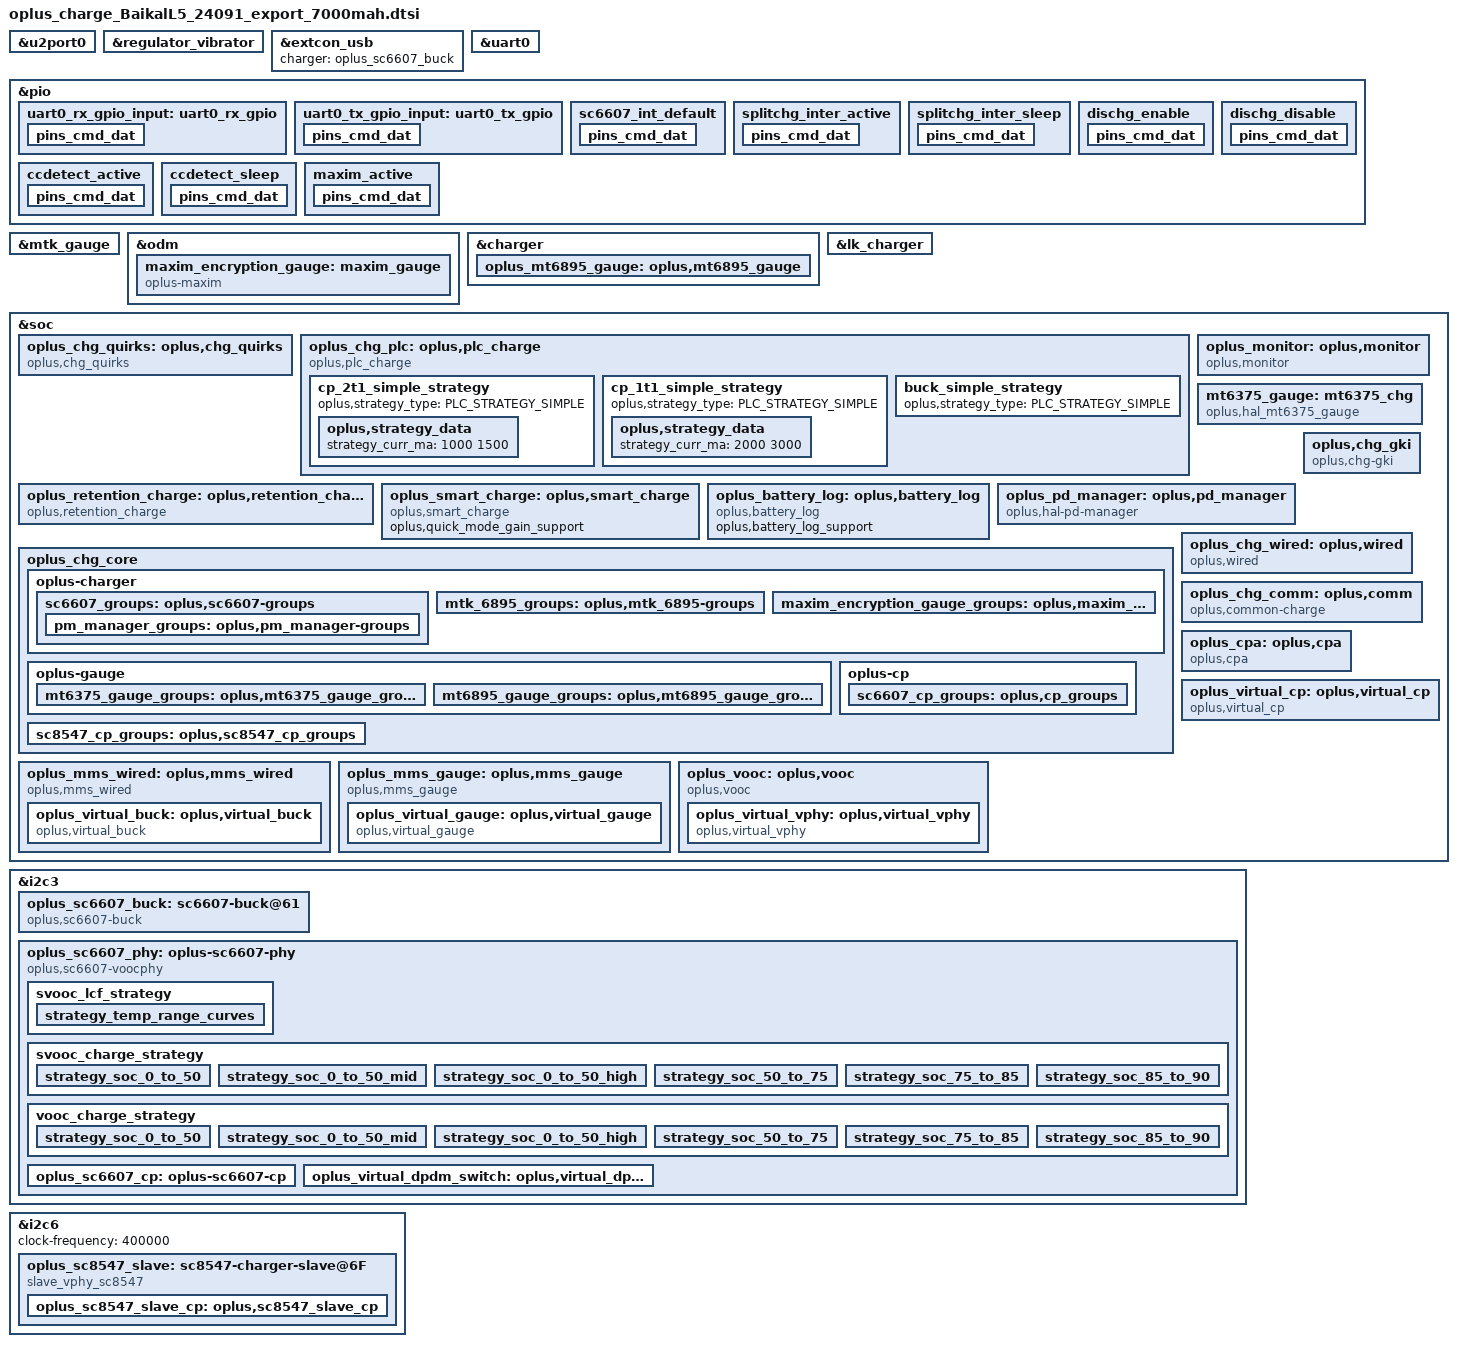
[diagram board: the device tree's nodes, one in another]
// SPDX-License-Identifier: GPL-2.0-only
/*
* Copyright (C) 2021-2020 Oplus. All rights reserved.
*/

/*
 * CPU:MT6835
 * Project:Baikal-L5
 * Module:CHG dtsi 80W support svooc,PPS
 *
 * UART
 * UTXD0 -->GPIO50
 * URXD0 -->GPIO51
 *
 * I2C
 * MASTER_CHG/CCLOGIC --> I2C5
 * Slave_CP --> I2C6
 *
 * IRQ
 * EINT5(PD IRQ)                -->GPIO5
 * EINT6(CHG IRQ)               -->GPIO6
 * EINT18(CP2 IRQ)               -->GPIO18
 *
 * GPIO
 * MAIN/CCLOGIN_SCL               --> GPIO137(SCL5)
 * MAIN/CCLOGIN_SDA               --> GPIO138(SDA5)
 * VBUS_SHORT(防烧口)             --> GPIO34
 * SEC_IC (加密电池GPIO for 80W)      --> GPIO3
 *
 * AP_AUXADC:
 * 0				--> FLASH_LED_NTC (flash light temperature)
 * 1				--> NA
 * 2				--> CHG_NTC(sc6607 charger temperature)
 * 3				--> USB_TEM_ADC_PMU1(usb btb temperature)
 * 4				--> USB_TEM_ADC_PMU2(usb btb temperature)
 * 5				--> BAT_ID(battery id detect)
 * 6				--> TSBAT(Main board battery btb temperature)
 * 7				-->
 * 8				-->
 */

#include <dt-bindings/iio/mt635x-auxadc.h>
#include <dt-bindings/pinctrl/mt6373-pinfunc.h>
#include <dt-bindings/pinctrl/mt65xx.h>
#include "oplus_chg.h"

&u2port0 {
	mediatek,eye-vrt = <7>;
	mediatek,eye-term= <5>;
	mediatek,rev6 = <2>;
	mediatek,eye-vrt-host = <7>;
	mediatek,eye-term-host = <4>;
	mediatek,rev6-host = <2>;
	mediatek,discth = <0xc>;
	mediatek,rx-sqth = <3>;
};

&regulator_vibrator{
	min-volt = <3000000>;
	max-volt = <3000000>;
};

&extcon_usb {
	charger = <&oplus_sc6607_buck>;
	status = "okay";
};

&uart0 {
	pinctrl-names = "uart0_rx_gpio", "uart0_tx_gpio";
	pinctrl-0 = <&uart0_rx_gpio_input>;
	pinctrl-1 = <&uart0_tx_gpio_input>;
	status = "okay";

	txpin = <50>;
	rxpin = <51>;
};

&pio {
	uart0_rx_gpio_input: uart0_rx_gpio {
		pins_cmd_dat {
			pinmux = <PINMUX_GPIO51__FUNC_GPIO51>;
			input-enable;
			slew-rate = <0>;
			bias-disable;
		};
	};

	uart0_tx_gpio_input: uart0_tx_gpio {
		pins_cmd_dat {
			pinmux = <PINMUX_GPIO50__FUNC_GPIO50>;
			input-enable;
			slew-rate = <0>;
			bias-disable;
		};
	};
	sc6607_int_default: sc6607_int_default {
		pins_cmd_dat {
			pinmux = <PINMUX_GPIO6__FUNC_GPIO6>;
			input-enable;
			bias-disable;
			slew-rate = <0>;
		};
	};
	/*split_chg*/
	splitchg_inter_active: splitchg_inter_active {
		pins_cmd_dat {
			pinmux = <PINMUX_GPIO6__FUNC_GPIO6>;
			input-enable;
			bias-pull-up;
			slew-rate = <0>;
		};
	};
	splitchg_inter_sleep: splitchg_inter_sleep {
		pins_cmd_dat {
			pinmux = <PINMUX_GPIO6__FUNC_GPIO6>;
			input-enable;
			bias-pull-down;
			slew-rate = <0>;
		};
	};
	/*VBUS_SHORT*/
	dischg_enable: dischg_enable {
		pins_cmd_dat {
			pinmux = <PINMUX_GPIO34__FUNC_GPIO34>;
			output-high;
		};
	};
	dischg_disable: dischg_disable {
		pins_cmd_dat {
			pinmux = <PINMUX_GPIO34__FUNC_GPIO34>;
			output-low;
		};
	};
	ccdetect_active: ccdetect_active {
		pins_cmd_dat {
			pinmux = <PINMUX_GPIO10__FUNC_GPIO10>;
			input-enable;
			slew-rate = <0>;
			bias-disable;
		};
	};
	ccdetect_sleep: ccdetect_sleep {
		pins_cmd_dat {
			pinmux = <PINMUX_GPIO10__FUNC_GPIO10>;
			input-enable;
			slew-rate = <0>;
			bias-disable;
		};
	};
	maxim_active: maxim_active {
		pins_cmd_dat {
			pinmux = <PINMUX_GPIO3__FUNC_GPIO3>;
			drive-strength = <6>;
			bias-pull-up;
		};
	};
};


&mtk_gauge {
	status = "okay";
	charger = <&oplus_sc6607_buck>;
	//SHUTDOWN_1_TIME = <(10)>;
	FUELGAGUE_APPLY = <(1)>;
	EXTERNAL_AUTHENTICATE =<(1)>;
	IS_SUBBOARD_TEMP_SUPPORT = <(0)>;
	RBAT_PULL_DOWN_R = <(24000)>;
	RBAT_PULL_UP_R = <(12000)>;
	RBAT_PULL_UP_VOLT = <(2800)>;
	USE_MORE_PRECISE_NTC_TABLE = <(1)>;
	//NTC_SERIES_R = <(5100)>;
	FG_METER_RESISTANCE = <(45)>; /* The resistance of PCB */
	CAR_TUNE_VALUE = <(101)>; /* Tune value for current measurement */
	BATT_ID_NEW_4450_CHECK = <(1)>;
	IS_SUBBOARD_TEMP_SUPPORT = <(0)>;
	R_FG_VALUE = <(2)>; /* R_sense resistance */
	oplus,ftm_force_batid = <(1)>; /*need check*/
	AGING_FACTOR_DIFF = <(1)>;
	ACTIVE_TABLE = <(5)>;
	TEMPERATURE_T4 = <(-10)>;
	KEEP_100_PERCENT = <2>;
	KEEP_100_PERCENT_MINSOC = <9500>;
	PSEUDO100_EN = <1>;
	PSEUDO100_EN_DIS = <0>;

	io-channels = <&pmic_adc AUXADC_BAT_TEMP>,
				<&pmic_adc AUXADC_BATADC>,
				<&pmic_adc AUXADC_VBIF>,
				<&pmic_adc AUXADC_IMP>,
				<&pmic_adc AUXADC_IMIX_R>,
				<&auxadc 5>;
	io-channel-names = "pmic_battery_temp",
			   "pmic_battery_voltage",
			   "pmic_bif_voltage",
			   "pmic_ptim_voltage",
			   "pmic_ptim_r",
			   "auxadc5-batt_id_v";


    //IS_SUBBOARD_TEMP_SUPPORT = <(1)>;
	Enable_Is_Force_Full = <(1)>;
	DIM2_TABLE_DISTINGUISH = <(1)>;
	#include "mediatek/bat_setting/mt6835_battery_table_Baikal_L5_7000mah.dtsi"
	#include "mediatek/bat_setting/mt6835_battery_prop_dim2_ext_Baikal_L5.dtsi"
};

&odm {
	maxim_encryption_gauge: maxim_gauge {
		status = "okay";
		compatible = "oplus-maxim";
		pinctrl-names = "maxim_active";
		pinctrl-0 = <&maxim_active>;
		support_encryption_in_lk;
		data-gpio = <&pio 3 0x00>;
		gpio-addr-set-out = <0x10005004>;
		gpio-addr-set-in = <0x10005008>;
		gpio-addr-level_high = <0x10005104>;
		gpio-addr-level_low = <0x10005108>;
		gpio-addr-data-in = <0x10005200>;
		gpio-addr-offset = <0x16>;

		oplus,batt_info = /bits/ 8 <0x36 0x31 0x31 0x33 0x30 0x33 0x30 0x30 0x30 0x32 0x35 0x33
					    0x36 0x31 0x31 0x33 0x30 0x33 0x30 0x30 0x30 0x32 0x35 0x34
					    0x36 0x31 0x31 0x33 0x30 0x33 0x30 0x30 0x30 0x32 0x35 0x35
					    0x36 0x31 0x31 0x33 0x30 0x33 0x30 0x30 0x30 0x32 0x35 0x37>;
		oplus,ic_type = <OPLUS_CHG_IC_GAUGE>;
		oplus,ic_index = <2>;
	};
};

&charger {
	io-channels =<&auxadc 6>,<&auxadc 2>;
	io-channel-names = "auxadc1-ntc_sub_bat_tem","auxadc5-chargeric_temp";
	oplus,support_ntc_01c_precision;
	oplus,support_subboard_ntc;
	oplus,support_subboard_parameter = <1 1 4397119 200000 1800 (-400) 1250 2457>;
	oplus,support_subboard_table = <
	(-40) 4397119 (-40) 4092874 (-40) 3811717 (-40) 3551749 (-40) 3311236 (-40) 3088599
	(-40) 2882396 (-40) 2691310 (-40) 2514137 (-40) 2349778 (-40) 2197225 (-40) 2055558
	(-40) 1923932 (-40) 1801573 (-40) 1687773 (-40) 1581881 (-40) 1483100 (-40) 1391113
	(-40) 1305413 (-40) 1225531 (-40) 1151037 (-40) 1081535 (-40) 1016661 (-40)  956080
	(-40)  899481 (-15) 846579  (-14) 797111  (-13) 750834  (-12)  707524 (-11)  666972
	(-10)  628988 (-9)  593342  (-8)  559931  (-7)  528602  (-6)  499212  (-5)   471632
	(-4)   445772 (-3)  421480  (-2)   398652 (-1) 377193    0    357012   1     338006
	2    320122 3    303287 4    287434 5    272500 6    258426 7    245160
	8    232649 9    220847 10   209710 11   199196 12   189268 13   179890
	14   171028 15   162651 16   154726 17   147232 18   140142 19   133432
	20   127080 21   121066 22   115368 23   109970 24   104852 25   100000
	26   95398  27   91032  28   86889  29   82956  30   79222  31   75675
	32   72306  33   69104  34   66061  35   63167  36   60415  37   57797
	38   55306  39   52934  40   50677  41   48528  42   46482  43   44533
	44   42675  45   40904  46   39213  47   37601  48   36063  49   34595
	50   33195  51   31859  52   30584  53   29366  54   28203  55   27091
	56   26028  57   25013  58   24042  59   23113  60   22224  61   21374
	62   20561  63   19782  64   19036  65   18323  66   17640  67   16986
	68   16360  69   15760  70   15184  71   14631  72   14101  73   13592
	74   13104  75   12635  76   12187  77   11757  78   11344  79   10947
	80   10566  81   10200  82   9848   83   9510   84   9185   85   8873
	86   8572   87   8283   88   8006   89   7738   90   7481   91   7234
	92   6997   93   6769   94   6548   95   6337   96   6132   97   5934
	98   5744   99   5561   100  5384   101  5214   102  5051   103  4893
	104  4741   105  4594   106  4453   107  4316   108  4184   109  4057
	110  3934   111  3816   112  3701   113  3591   114  3484   115  3380
	116  3281   117  3185   118  3093   119  3003   120  2916   121  2832
	122  2751   123  2672   124  2596   125  2522   125  2522   125  2522
	125  2522   125  2522   125   2522  125  2522   125  2522   125  2522
	125  2522   125  2522   125   2522  125  2522   125  2522   125  2522 >;
	max_charger_voltage = <15000000>;
	gauge = <&mtk_gauge>;
	charger = <&oplus_sc6607_buck>;

	oplus,ic_type = <OPLUS_CHG_IC_BUCK>;
	oplus,ic_index = <1>;

	oplus_mt6895_gauge: oplus,mt6895_gauge {
		oplus,ic_type = <OPLUS_CHG_IC_GAUGE>;
		oplus,ic_index = <1>;
	};
};

&lk_charger {
	en_vol_ctrl_vibrate = <3200>;
	support_tuv_authentication;
	support_maxim_battery_authentication;
	data-gpio = <3>;
	oplus,batt_info = /bits/ 8 <0x36 0x31 0x31 0x33 0x30 0x33 0x30 0x30 0x30 0x32 0x35 0x33
				    0x36 0x31 0x31 0x33 0x30 0x33 0x30 0x30 0x30 0x32 0x35 0x34
				    0x36 0x31 0x31 0x33 0x30 0x33 0x30 0x30 0x30 0x32 0x35 0x35
				    0x36 0x31 0x31 0x33 0x30 0x33 0x30 0x30 0x30 0x32 0x35 0x37>;
	charger_no_wiress;
	sdp_screenon_voltage = <3250>;
	sub_board_temp_support;
	sub_board_pull_up_voltage = <1840>;
	sub_board_max_volt_range = <1450>;
	sub_board_pull_up_r = <200000>;
	sub_board_adc_channel = <6>;
	subboard_use_ap_auxadc;
	support_sdp_screenoff;
	support_sdp_backlight;
	led_brightness = <102>;
	high-temp-scheme;
	over_high_temp_thr = <60>;
	support_quickboot_charge;
	is_support_sc6607;
	support_4p48_single_battery;//待确定
	max_charger_voltage = <15000000>;
	boot_battery_voltage = <3400000>;
	usb_charger_current = <500000>;
	ac_charger_current = <2050000>;
	ac_charger_input_current = <1500000>;
	non_std_ac_charger_current = <750000>;
	charging_host_charger_current = <1500000>;
	ta_ac_charger_current = <1500000>;
	pd_charger_current = <500000>;
};

&soc {
	oplus_chg_quirks: oplus,chg_quirks {
		compatible = "oplus,chg_quirks";
	};

	oplus_chg_plc: oplus,plc_charge {
		compatible = "oplus,plc_charge";
		oplus,plc_soc = <90>;
		oplus,plc_strategy-data = <&buck_simple_strategy>;
		oplus,plc_strategy-names = "default";

		cp_2t1_simple_strategy: cp_2t1_simple_strategy {
			oplus,strategy_type = <PLC_STRATEGY_SIMPLE>;
			oplus,strategy_data {
				strategy_curr_ma = <1000 1500>;
			};
		};

		cp_1t1_simple_strategy: cp_1t1_simple_strategy {
			oplus,strategy_type = <PLC_STRATEGY_SIMPLE>;
			oplus,strategy_data {
				strategy_curr_ma = <2000 3000>;
			};
		};

		buck_simple_strategy: buck_simple_strategy {
			oplus,strategy_type = <PLC_STRATEGY_SIMPLE>;
		};
	};

	oplus_retention_charge: oplus,retention_charge {
		compatible = "oplus,retention_charge";
		oplus,topic-update-interval = <5000>;
		oplus,support_retention_name = "oplus_retention_quirks";
	};

	oplus_smart_charge: oplus,smart_charge {
		compatible = "oplus,smart_charge";
		oplus,quick_mode_gain_support;
	};

	oplus_battery_log: oplus,battery_log {
		compatible = "oplus,battery_log";
		oplus,battery_log_support;
	};

	oplus_monitor: oplus,monitor {
		compatible = "oplus,monitor";
		oplus,topic-update-interval = <60000>;

		track,fast_chg_break_t_thd = <1000>;
		track,general_chg_break_t_thd = <200>;
		track,voocphy_type = <3>;
		track,wired_max_power = <80000>;
		track,wired_fast_chg_scheme = <2>;
	};

	mt6375_gauge: mt6375_chg {
		status = "okay";
		compatible = "oplus,hal_mt6375_gauge";

		oplus,ic_type = <OPLUS_CHG_IC_GAUGE>;
		oplus,ic_index = <0>;
		oplus,batt_num = <1>;
		oplus,mtk_gauge_power_sel_support;
		oplus,mtk_gauge_power_sel_by_power_support;
		oplus,mtk_gauge_cali_track_support;
	};

	oplus_pd_manager: oplus,pd_manager{
		compatible = "oplus,hal-pd-manager";
		oplus,ic_type = <OPLUS_CHG_IC_TYPEC>;
		oplus,ic_index = <0>;
	};

	oplus,chg_gki {
		compatible = "oplus,chg-gki";
	};

	oplus_chg_core {
		oplus,chg_framework_v2;
		oplus,chg_spec_version = <OPLUS_CHG_SPEC_VER_V3P7>;
		oplus,smart_charging_screenoff;

		oplus-charger {
			sc6607_groups: oplus,sc6607-groups {
				functions = <
					OPLUS_IC_FUNC_INIT
					OPLUS_IC_FUNC_EXIT
					OPLUS_IC_FUNC_REG_DUMP
					OPLUS_IC_FUNC_SMT_TEST
					OPLUS_IC_FUNC_BUCK_INPUT_PRESENT
					OPLUS_IC_FUNC_BUCK_INPUT_SUSPEND
					OPLUS_IC_FUNC_BUCK_INPUT_IS_SUSPEND
					OPLUS_IC_FUNC_BUCK_OUTPUT_SUSPEND
					OPLUS_IC_FUNC_BUCK_OUTPUT_IS_SUSPEND
					OPLUS_IC_FUNC_BUCK_SET_ICL
					OPLUS_IC_FUNC_BUCK_GET_ICL
					OPLUS_IC_FUNC_BUCK_SET_FCC
					OPLUS_IC_FUNC_BUCK_SET_FV
					OPLUS_IC_FUNC_BUCK_SET_ITERM
					OPLUS_IC_FUNC_BUCK_SET_RECHG_VOL
					OPLUS_IC_FUNC_BUCK_GET_INPUT_CURR
					OPLUS_IC_FUNC_BUCK_GET_INPUT_VOL
					OPLUS_IC_FUNC_OTG_BOOST_ENABLE
					OPLUS_IC_FUNC_SET_OTG_BOOST_VOL
					OPLUS_IC_FUNC_BUCK_AICL_ENABLE
					OPLUS_IC_FUNC_BUCK_AICL_RERUN
					OPLUS_IC_FUNC_BUCK_AICL_RESET
					OPLUS_IC_FUNC_BUCK_GET_CHARGER_TYPE
					OPLUS_IC_FUNC_BUCK_RERUN_BC12
					OPLUS_IC_FUNC_BUCK_QC_DETECT_ENABLE
					OPLUS_IC_FUNC_BUCK_SET_QC_CONFIG
					OPLUS_IC_FUNC_BUCK_SHIPMODE_ENABLE
					OPLUS_IC_FUNC_BUCK_GET_USB_BTB_TEMP
					OPLUS_IC_FUNC_BUCK_GET_BATT_BTB_TEMP
					OPLUS_IC_FUNC_BUCK_SET_AICL_POINT
					OPLUS_IC_FUNC_BUCK_HARDWARE_INIT
					OPLUS_IC_FUNC_BUCK_KICK_WDT
					OPLUS_IC_FUNC_BUCK_GET_USB_AICL_ENHANCE
					OPLUS_IC_FUNC_BUCK_SET_FLASH_MODE
					OPLUS_IC_FUNC_BUCK_SET_PD_CONFIG
				>;
				virqs = <
					OPLUS_IC_VIRQ_ERR
					OPLUS_IC_VIRQ_PLUGIN
					OPLUS_IC_VIRQ_CHG_TYPE_CHANGE
					OPLUS_IC_VIRQ_BC12_COMPLETED
				>;
				pm_manager_groups: oplus,pm_manager-groups {
					functions = <
						OPLUS_IC_FUNC_INIT
						OPLUS_IC_FUNC_EXIT
						OPLUS_IC_FUNC_REG_DUMP
						OPLUS_IC_FUNC_SMT_TEST
						OPLUS_IC_FUNC_BUCK_GET_CHARGER_TYPE
						OPLUS_IC_FUNC_BUCK_GET_CC_ORIENTATION
						OPLUS_IC_FUNC_BUCK_SET_PD_CONFIG
						OPLUS_IC_FUNC_GET_TYPEC_MODE
						OPLUS_IC_FUNC_SET_TYPEC_MODE
						OPLUS_IC_FUNC_GET_TYPEC_ROLE
						OPLUS_IC_FUNC_GET_CHARGER_VOL_MAX
						OPLUS_IC_FUNC_GET_CHARGER_VOL_MIN
						OPLUS_IC_FUNC_GET_CHARGER_CURR_MAX
						OPLUS_IC_FUNC_BUCK_BC12_COMPLETED
						OPLUS_IC_FUNC_GET_OTG_ENABLE
						OPLUS_IC_FUNC_IS_OPLUS_SVID
						OPLUS_IC_FUNC_GET_DATA_ROLE
						OPLUS_IC_FUNC_FIXED_PDO_SET
						OPLUS_IC_FUNC_PPS_PDO_SET
						OPLUS_IC_FUNC_PPS_GET_PDO_INFO
					>;
					virqs = <
						OPLUS_IC_VIRQ_ERR
						OPLUS_IC_VIRQ_CHG_TYPE_CHANGE
						OPLUS_IC_VIRQ_SVID
						OPLUS_IC_VIRQ_VOLTAGE_CHANGED
						OPLUS_IC_VIRQ_CURRENT_CHANGED
						OPLUS_IC_VIRQ_OTG_ENABLE
						OPLUS_IC_VIRQ_DATA_ROLE_CHANGED
						OPLUS_IC_VIRQ_CC_DETECT
					>;
				};
			};
			mtk_6895_groups: oplus,mtk_6895-groups {
				functions = <
					OPLUS_IC_FUNC_INIT
					OPLUS_IC_FUNC_EXIT
					OPLUS_IC_FUNC_REG_DUMP
					OPLUS_IC_FUNC_SMT_TEST
				>;
				virqs = <
					OPLUS_IC_VIRQ_ERR
				>;
			};

			maxim_encryption_gauge_groups: oplus,maxim_encryption_gauge_groups {
				functions = <
					OPLUS_IC_FUNC_INIT
					OPLUS_IC_FUNC_EXIT
					OPLUS_IC_FUNC_GAUGE_GET_BATT_AUTH
				>;
				virqs = <
					OPLUS_IC_VIRQ_ERR
				>;
			};
		};

		oplus-gauge {
			mt6375_gauge_groups: oplus,mt6375_gauge_groups {
				functions = <
					OPLUS_IC_FUNC_INIT
					OPLUS_IC_FUNC_EXIT
					OPLUS_IC_FUNC_REG_DUMP
					OPLUS_IC_FUNC_SMT_TEST
					OPLUS_IC_FUNC_GAUGE_GET_BATT_VOL
					OPLUS_IC_FUNC_GAUGE_GET_BATT_MAX
					OPLUS_IC_FUNC_GAUGE_GET_BATT_MIN
					OPLUS_IC_FUNC_GAUGE_GET_BATT_CURR
					OPLUS_IC_FUNC_GAUGE_GET_BATT_TEMP
					OPLUS_IC_FUNC_GAUGE_GET_BATT_SOC
					OPLUS_IC_FUNC_GAUGE_GET_BATT_FCC
					OPLUS_IC_FUNC_GAUGE_GET_BATT_CC
					OPLUS_IC_FUNC_GAUGE_GET_BATT_RM
					OPLUS_IC_FUNC_GAUGE_GET_BATT_SOH
					OPLUS_IC_FUNC_GAUGE_GET_BATT_HMAC
					OPLUS_IC_FUNC_GAUGE_SET_BATT_FULL
					OPLUS_IC_FUNC_GAUGE_UPDATE_DOD0
					OPLUS_IC_FUNC_GAUGE_UPDATE_SOC_SMOOTH
					OPLUS_IC_FUNC_GAUGE_GET_CB_STATUS
					OPLUS_IC_FUNC_GAUGE_GET_BATT_NUM
					OPLUS_IC_FUNC_GAUGE_GET_DEVICE_TYPE
					OPLUS_IC_FUNC_GAUGE_GET_DEVICE_TYPE_FOR_VOOC
					OPLUS_IC_FUNC_GAUGE_GET_BATT_FCC
					OPLUS_IC_FUNC_GAUGE_GET_BATT_FC
					OPLUS_IC_FUNC_GAUGE_GET_BATT_QM
					OPLUS_IC_FUNC_GAUGE_GET_BATT_PD
					OPLUS_IC_FUNC_GAUGE_GET_BATT_RCU
					OPLUS_IC_FUNC_GAUGE_GET_BATT_RCF
					OPLUS_IC_FUNC_GAUGE_GET_BATT_FCU
					OPLUS_IC_FUNC_GAUGE_GET_BATT_FCF
					OPLUS_IC_FUNC_GAUGE_GET_BATT_SOU
					OPLUS_IC_FUNC_GAUGE_GET_BATT_DO0
					OPLUS_IC_FUNC_GAUGE_GET_BATT_DOE
					OPLUS_IC_FUNC_GAUGE_GET_BATT_TRM
					OPLUS_IC_FUNC_GAUGE_GET_BATT_PC
					OPLUS_IC_FUNC_GAUGE_GET_BATT_QS
					OPLUS_IC_FUNC_GAUGE_IS_SUSPEND
					OPLUS_IC_FUNC_GAUGE_GET_BCC_PARMS
					OPLUS_IC_FUNC_GAUGE_FASTCHG_UPDATE_BCC_PARMS
					OPLUS_IC_FUNC_GAUGE_GET_PREV_BCC_PARMS
					OPLUS_IC_FUNC_GAUGE_SET_BCC_PARMS
					OPLUS_IC_FUNC_GAUGE_SET_PROTECT_CHECK
					OPLUS_IC_FUNC_GAUGE_GET_AFI_UPDATE_DONE
					OPLUS_IC_FUNC_GAUGE_CHECK_RESET
					OPLUS_IC_FUNC_GAUGE_GET_DEVICE_TYPE_FOR_BCC
					OPLUS_IC_FUNC_GAUGE_GET_DOD0
					OPLUS_IC_FUNC_GAUGE_GET_DOD0_PASSED_Q
					OPLUS_IC_FUNC_GAUGE_GET_QMAX
					OPLUS_IC_FUNC_GAUGE_GET_QMAX_PASSED_Q
					OPLUS_IC_FUNC_GAUGE_SET_BATTERY_CURVE
					OPLUS_IC_FUNC_GAUGE_GET_GAUGE_TYPE
					OPLUS_IC_FUNC_GAUGE_GET_GAUGE_CAR_C
					OPLUS_IC_FUNC_GAUGE_GET_DEC_FG_TYPE
					OPLUS_IC_FUNC_GAUGE_GET_DEC_CV_SOH
					OPLUS_IC_FUNC_GAUGE_SET_VCT
					OPLUS_IC_FUNC_GAUGE_GET_VCT
				>;
				virqs = <
					OPLUS_IC_VIRQ_ERR
					OPLUS_IC_VIRQ_OFFLINE
					OPLUS_IC_VIRQ_RESUME
				>;
			};

			mt6895_gauge_groups: oplus,mt6895_gauge_groups {
				functions = <
					OPLUS_IC_FUNC_INIT
					OPLUS_IC_FUNC_EXIT
					OPLUS_IC_FUNC_GAUGE_GET_SUBBOARD_TEMP
				>;
				virqs = <
					OPLUS_IC_VIRQ_ERR
				>;
			};
		};

		oplus-cp {
			sc6607_cp_groups: oplus,cp_groups {
			functions = <
					OPLUS_IC_FUNC_INIT
					OPLUS_IC_FUNC_EXIT
					OPLUS_IC_FUNC_REG_DUMP
					OPLUS_IC_FUNC_SMT_TEST
					OPLUS_IC_FUNC_CP_ENABLE
					OPLUS_IC_FUNC_CP_HW_INTI
					OPLUS_IC_FUNC_CP_GET_WORK_MODE
					OPLUS_IC_FUNC_CP_CHECK_WORK_MODE_SUPPORT
					OPLUS_IC_FUNC_CP_SET_WORK_MODE
					OPLUS_IC_FUNC_CP_GET_VIN
					OPLUS_IC_FUNC_CP_GET_IIN
					OPLUS_IC_FUNC_CP_SET_IIN
					OPLUS_IC_FUNC_CP_GET_VOUT
					OPLUS_IC_FUNC_CP_GET_IOUT
					OPLUS_IC_FUNC_CP_GET_VAC
					OPLUS_IC_FUNC_CP_SET_IIN
					OPLUS_IC_FUNC_CP_SET_WORK_START
					OPLUS_IC_FUNC_CP_GET_WORK_STATUS
					OPLUS_IC_FUNC_CP_SET_ADC_ENABLE
					OPLUS_IC_FUNC_CP_WATCHDOG_ENABLE
					OPLUS_IC_FUNC_CP_WATCHDOG_RESET
					OPLUS_IC_FUNC_CP_SET_UCP_DISABLE
					OPLUS_IC_FUNC_CP_GET_IIN_MAX
				>;
				virqs = <
					OPLUS_IC_VIRQ_ERR
					OPLUS_IC_VIRQ_ONLINE
					OPLUS_IC_VIRQ_OFFLINE
				>;
			};
		};
		sc8547_cp_groups: oplus,sc8547_cp_groups {
				functions = <
					OPLUS_IC_FUNC_INIT
					OPLUS_IC_FUNC_EXIT
					OPLUS_IC_FUNC_REG_DUMP
					OPLUS_IC_FUNC_SMT_TEST
					OPLUS_IC_FUNC_CP_ENABLE
					OPLUS_IC_FUNC_CP_HW_INTI
					OPLUS_IC_FUNC_CP_SET_WORK_START
					OPLUS_IC_FUNC_CP_CHECK_WORK_MODE_SUPPORT
					OPLUS_IC_FUNC_CP_SET_WORK_MODE
					OPLUS_IC_FUNC_CP_GET_WORK_MODE
					OPLUS_IC_FUNC_CP_GET_VIN
					OPLUS_IC_FUNC_CP_GET_IIN
					OPLUS_IC_FUNC_CP_SET_IIN
					OPLUS_IC_FUNC_CP_GET_VOUT
					OPLUS_IC_FUNC_CP_GET_IOUT
					OPLUS_IC_FUNC_CP_GET_VAC
					OPLUS_IC_FUNC_CP_GET_WORK_STATUS
					OPLUS_IC_FUNC_CP_SET_ADC_ENABLE
					OPLUS_IC_FUNC_CP_WATCHDOG_ENABLE
				>;
				virqs = <
					OPLUS_IC_VIRQ_ERR
					OPLUS_IC_VIRQ_ONLINE
					OPLUS_IC_VIRQ_OFFLINE
				>;
			};
	};
};

&soc {
	oplus_mms_wired: oplus,mms_wired {
		compatible = "oplus,mms_wired";
		oplus,buck_ic = <&oplus_virtual_buck>;
		oplus,voocphy_ic = <&oplus_virtual_vphy>;
		oplus,adc_info_name = "100k_1800mv";
		oplus_spec,usbtemp_batttemp_gap = <12>;
		high-temp-scheme;

		oplus,support_usbtemp_protect_v2;
		oplus_spec,usbtemp_batt_temp_low = <50>;
		oplus_spec,usbtemp_batt_temp_high = <50>;
		oplus_spec,usbtemp_batt_temp_over_hot = <60>;
		oplus_spec,usbtemp_ntc_temp_low = <57>;
		oplus_spec,usbtemp_ntc_temp_high = <69>;
		oplus_spec,usbtemp_temp_gap_low_with_batt_temp = <7>;
		oplus_spec,usbtemp_temp_gap_with_batt_temp_in_over_hot = <15>;
		oplus_spec,usbtemp_temp_gap_high_with_batt_temp = <12>;
		oplus_spec,usbtemp_temp_gap_low_without_batt_temp = <12>;
		oplus_spec,usbtemp_temp_gap_high_without_batt_temp = <24>;
		oplus_spec,usbtemp_rise_fast_temp_low = <3>;
		oplus_spec,usbtemp_rise_fast_temp_high = <3>;
		oplus_spec,usbtemp_rise_fast_temp_count_low = <30>;
		oplus_spec,usbtemp_rise_fast_temp_count_high = <20>;
		oplus_spec,usbtemp_cool_down_ntc_low = <54>;
		oplus_spec,usbtemp_cool_down_ntc_high = <65>;
		oplus_spec,usbtemp_cool_down_gap_low = <12>;
		oplus_spec,usbtemp_cool_down_gap_high = <20>;
		oplus_spec,usbtemp_cool_down_recover_ntc_low = <48>;
		oplus_spec,usbtemp_cool_down_recover_ntc_high = <60>;
		oplus_spec,usbtemp_cool_down_recover_gap_low = <6>;
		oplus_spec,usbtemp_cool_down_recover_gap_high = <15>;
		oplus_virtual_buck: oplus,virtual_buck {
			compatible = "oplus,virtual_buck";
			oplus,buck_ic = <&oplus_sc6607_buck &oplus_pd_manager &charger>;
			oplus,buck_ic_index = <0 1 2>;
			oplus,buck_ic_current_ratio = <100 0 0>;
			oplus,buck_ic_connect = <OPLUS_CHG_IC_CONNECT_PARALLEL>;
			oplus,main_charger = <0>;
			oplus,buck_ic_func_group = <&sc6607_groups &pm_manager_groups &mtk_6895_groups>;
			oplus,ic_type = <OPLUS_CHG_IC_VIRTUAL_BUCK>;
			oplus,ic_index = <0>;
			oplus,dischg-gpio = <&pio 34 0x00>;/*VBUS_SHORT*/
			oplus,ccdetect-gpio = <&pio 10 0x00>;
			oplus,uart_tx-gpio = <&pio 50 0x00>;
			oplus,uart_rx-gpio = <&pio 51 0x00>;
			pinctrl-names = "dischg_enable", "dischg_disable",
						"ccdetect_active", "ccdetect_sleep";
			pinctrl-0 = <&dischg_enable>;
			pinctrl-1 = <&dischg_disable>;
			pinctrl-2 = <&ccdetect_active>;
			pinctrl-3 = <&ccdetect_sleep>;
			io-channels = <&auxadc 4>,<&auxadc 3>;
			io-channel-names = "usb_temp_adc_l","usb_temp_adc_r";
		};
	};
	oplus_mms_gauge: oplus,mms_gauge {
		compatible = "oplus,mms_gauge";
		oplus,voocphy_ic = <&oplus_virtual_vphy>;
		oplus,gauge_ic = <&oplus_virtual_gauge>;
		oplus,topic-update-interval = <10000>;
		oplus,support_subboard_ntc;
		oplus_virtual_gauge: oplus,virtual_gauge {
			compatible = "oplus,virtual_gauge";
			oplus,gauge_ic = <&mt6375_gauge &oplus_mt6895_gauge &maxim_encryption_gauge>;
			oplus,gauge_ic_index = <0 1 2>;
			oplus,gauge_ic_func_group = <&mt6375_gauge_groups &mt6895_gauge_groups &maxim_encryption_gauge_groups>;
			oplus,batt_capacity_mah = <7000>;
			oplus,ic_type = <OPLUS_CHG_IC_VIRTUAL_GAUGE>;
			oplus,ic_index = <0>;
		};
	};
};

&soc {
	oplus_chg_wired: oplus,wired {
		compatible = "oplus,wired";
		oplus,vooc-support;
		oplus_spec,vbatt_pdqc_to_5v_thr = <4500>;
		oplus_spec,vbatt_pdqc_to_9v_thr = <4500>;
		oplus_spec,pd-iclmax-ma = <1500>;
		oplus_spec,qc-iclmax-ma = <1500>;
		oplus_spec,non-standard-ibatmax-ma = <500>;
		oplus_spec,input-power-mw = <
			2500		/* OPLUS_WIRED_CHG_MODE_UNKNOWN */
			2500		/* OPLUS_WIRED_CHG_MODE_SDP */
			7500		/* OPLUS_WIRED_CHG_MODE_CDP */
			10000		/* OPLUS_WIRED_CHG_MODE_DCP */
			18000		/* OPLUS_WIRED_CHG_MODE_VOOC */
			13500		/* OPLUS_WIRED_CHG_MODE_QC */
			13500		/* OPLUS_WIRED_CHG_MODE_PD */
		>;
		oplus_spec,led_on-fccmax-ma = <0 1707 3300 3300 3300 3300 3300 1000 0>;
		oplus_spec,fccmax-ma-lv = <
			0 1200 2200 2200 2200 2200 2200 2200 0	/* OPLUS_WIRED_CHG_MODE_UNKNOWN */
			0 600  600  600  600  600  600  600  0	/* OPLUS_WIRED_CHG_MODE_SDP */
			0 1600 1600 1600 1600 1600 1600 1600 0	/* OPLUS_WIRED_CHG_MODE_CDP */
			0 1707 2200 2200 2200 2200 2200 2200 0	/* OPLUS_WIRED_CHG_MODE_DCP */
			0 1707 3300 3300 3300 3300 3300 3300 0	/* OPLUS_WIRED_CHG_MODE_VOOC */
			0 1707 3300 3300 3300 3300 3300 3300 0	/* OPLUS_WIRED_CHG_MODE_QC */
			0 1707 3300 3300 3300 3300 3300 3300 0	/* OPLUS_WIRED_CHG_MODE_PD */
		>;
		oplus_spec,fccmax-ma-hv = <
			0 1200 2200 2200 2200 2200 2200 2200 0	/* OPLUS_WIRED_CHG_MODE_UNKNOWN */
			0 600  600  600  600  600  600  600  0	/* OPLUS_WIRED_CHG_MODE_SDP */
			0 1600 1600 1600 1600 1600 1600 1600 0	/* OPLUS_WIRED_CHG_MODE_CDP */
			0 1707 2200 2200 2200 2200 2200 2200 0	/* OPLUS_WIRED_CHG_MODE_DCP */
			0 1707 3300 3300 3300 3300 3300 3300 0	/* OPLUS_WIRED_CHG_MODE_VOOC */
			0 1707 3300 3300 3300 3300 3300 3300 0	/* OPLUS_WIRED_CHG_MODE_QC */
			0 1707 3300 3300 3300 3300 3300 3300 0	/* OPLUS_WIRED_CHG_MODE_PD */
		>;

		oplus_spec,cool_down_sale_pdqc_vol_mv = <5000>;
		oplus_spec,cool_down_sale_pdqc_curr_ma = <1200>;
		oplus_spec,cool_down_pdqc_vol_mv = <5000 5000 5000 9000>;
		oplus_spec,cool_down_pdqc_curr_ma = <1200 1500 2000 1500>;
		oplus_spec,cool_down_vooc_curr_ma = <1200 1500 2000 2500 3000 3000>;
		oplus_spec,cool_down_normal_curr_ma = <1200 1500 2000>;

		oplus_spec,vbus_ov_thr_mv = <10000 10000>;
		oplus_spec,vbus_uv_thr_mv = <4300 4300>;

		/* first data is strategy used temp type */
		oplus,vooc_strategy_name = "cgcl";
		oplus,vooc_strategy_data = <OPLUS_STRATEGY_USE_BATT_TEMP
					    0   350 3000 1 0
					    330 370 3000 2 0
					    350 440 2200 2 1>;
	};

	oplus_chg_comm: oplus,comm {
		compatible = "oplus,common-charge";
		oplus_spec,dec_step = <20>;
		oplus_spec,dec-vol-cc-full-thr = <0 400 600 800 1000 1200>;
		oplus_spec,dec-vol-fv-full-mv = <0 20 20 40 40 40>;
		oplus_spec,batt-them-thr = <(-100) 0 50 120 160 350 450 530>;
		oplus_spec,iterm-ma = <352>;
		oplus_spec,removed_bat_decidegc = <390>; /*-39 degree*/
		oplus_spec,fv-mv = <4490 4490 4490 4490 4490 4490 4470 4130 4130>;
		oplus_spec,sw-fv-mv = <4440 4440 4440 4440 4440 4440 4420 4080 4080>;
		oplus_spec,hw-fv-inc-mv = <0 18 18 18 18 18 18 18 0>;
		oplus_spec,sw-over-fv-mv = <4500 4500 4500 4500 4500 4500 4480 4140 4140>;
		oplus_spec,sw-over-fv-dec-mv = <8>;
		oplus_spec,non-standard-sw-fv-mv = <3930>;
		oplus_spec,non-standard-fv-mv = <3980>;
		oplus_spec,non-standard-hw-fv-inc-mv = <18>;
		oplus_spec,non-standard-sw-over-fv-mv = <3990>;
		oplus_spec,non-standard-vbatdet-mv = <3680>;
		oplus_spec,wired-vbatdet-mv = <0 4190 4290 4390 4390 4390 4370 4030 0>;
		oplus_spec,fcc-gear-thr-mv = <4180>;
		oplus_spec,vbatt-ov-thr-mv = <4600>;

		oplus_spec,full_pre_ffc_judge;
		oplus_spec,full-pre-ffc-mv = <4485>;
		oplus_spec,ffc-temp-thr = <120 210 350 440>;
		oplus_spec,wired-ffc-step-max = <2>;
		oplus_spec,wired-ffc-fv-mv = <4630 4630>;

		oplus_spec,wired-ffc-fv-cutoff-mv = <4565 4525 4525
						     4565 4505 4505>;
		oplus_spec,wired-ffc-fcc-ma = <1500 1500 1500
					       1440 1000 1000>;
		oplus_spec,wired-ffc-fcc-cutoff-ma = <1300 1300 1300
						      1340 900 900>;
		oplus_spec,vbat_uv_thr_mv = <3300>;
		oplus_spec,vbat_charging_uv_thr_mv = <3200>;

		/*If use subboard NTC as battery temp, config it as 20, otherwise 0 */
		oplus_spec,tbatt_power_off_cali_temp = <0>;
		oplus_spec,poweroff_high_batt_temp = <720>;
		oplus_spec,poweroff_emergency_batt_temp = <770>;
		oplus,vooc_show_ui_soc_decimal;
		oplus,ui_soc_decimal_speedmin = <20>;
		oplus,gauge_stuck_jump_support;
		oplus,gauge_stuck_threshold = <15>;
		oplus,gauge_stuck_time = <50>;
	};

	oplus_vooc: oplus,vooc {
		compatible = "oplus,vooc";
		oplus,vooc_ic = <&oplus_virtual_vphy>;
		oplus_spec,vooc_soc_range = <50 75 85>;
		oplus_spec,vooc_temp_range = <50 120 180 350 450>;
		oplus,vooc_data_width = <7>;
		oplus,vooc_curr_max = <CP_CURR_LIMIT_7BIT_15_0A>; /* 80W: 11V 7.3A(IBUS *2) */
		oplus,vooc_project = <7>;
		oplus,vooc_curr_table_type = <VOOC_CP_CURR_TABLE>;
		oplus,vooc_power_max_w = <80>;
		oplus,voocphy_support = <3>;  /* AP_DUAL_CP_VOOCPHY */
		oplus,support_fake_vooc_check;
		oplus,subboard_ntc_abnormal_current = <4000>;
		oplus,cp_cooldown_limit_percent_75 = <CP_CURR_LIMIT_7BIT_8_0A>;
		oplus,cp_cooldown_limit_percent_85 = <CP_CURR_LIMIT_7BIT_4_0A>;
		oplus,abnormal_adapter_current = <CP_CURR_LIMIT_7BIT_15_0A CP_CURR_LIMIT_7BIT_15_0A
						CP_CURR_LIMIT_7BIT_12_6A CP_CURR_LIMIT_7BIT_12_6A
						CP_CURR_LIMIT_7BIT_10_0A CP_CURR_LIMIT_7BIT_10_0A
						CP_CURR_LIMIT_7BIT_8_0A CP_CURR_LIMIT_7BIT_8_0A
						CP_CURR_LIMIT_7BIT_6_0A CP_CURR_LIMIT_7BIT_6_0A
						CP_CURR_LIMIT_7BIT_4_0A CP_CURR_LIMIT_7BIT_4_0A>;

		oplus,abnormal_over_80w_adapter_current = <CP_CURR_LIMIT_7BIT_15_0A CP_CURR_LIMIT_7BIT_15_0A
						CP_CURR_LIMIT_7BIT_14_0A CP_CURR_LIMIT_7BIT_14_0A
						CP_CURR_LIMIT_7BIT_12_0A CP_CURR_LIMIT_7BIT_12_0A
						CP_CURR_LIMIT_7BIT_10_0A CP_CURR_LIMIT_7BIT_10_0A
						CP_CURR_LIMIT_7BIT_8_0A CP_CURR_LIMIT_7BIT_8_0A
						CP_CURR_LIMIT_7BIT_6_0A CP_CURR_LIMIT_7BIT_6_0A
						CP_CURR_LIMIT_7BIT_4_0A CP_CURR_LIMIT_7BIT_4_0A>;
		/* first data is strategy used temp type */
		oplus,general_strategy_name = "cgcl";
		oplus,general_strategy_data = < OPLUS_STRATEGY_USE_SHELL_TEMP
						0   370 CP_CURR_LIMIT_7BIT_15_0A 1 0
						375 383 CP_CURR_LIMIT_7BIT_9_0A 2 0
						390 420 CP_CURR_LIMIT_7BIT_7_0A 3 1
						420 440 CP_CURR_LIMIT_7BIT_3_0A 3 2 >;

		oplus,bypass_strategy_name = "cgcl";
		oplus,bypass_strategy_data = <OPLUS_STRATEGY_USE_SHELL_TEMP
						0   350 CP_CURR_LIMIT_7BIT_6_0A  1 0
						340 380 CP_CURR_LIMIT_7BIT_5_0A  2 0
						370 440 CP_CURR_LIMIT_7BIT_4_0A  2 1>;

		oplus,plc_strategy-data = <&buck_simple_strategy &cp_2t1_simple_strategy &cp_1t1_simple_strategy>;
		oplus,plc_strategy-names = "default", "svooc", "vooc";

		oplus_virtual_vphy: oplus,virtual_vphy {
			compatible = "oplus,virtual_vphy";
			oplus,vphy_ic = <&oplus_sc6607_phy>;
			oplus,ic_type = <OPLUS_CHG_IC_VIRTUAL_VPHY>;
			oplus,ic_index = <0>;
		};
	};

	oplus_cpa: oplus,cpa {
		compatible = "oplus,cpa";
		oplus,protocol_list = <CHG_PROTOCOL_VOOC 80
							CHG_PROTOCOL_PPS 33
							CHG_PROTOCOL_PD 18>;
		oplus,default_protocol_list = <CHG_PROTOCOL_PPS
							CHG_PROTOCOL_PD
							CHG_PROTOCOL_VOOC>;
	};
	oplus_virtual_cp: oplus,virtual_cp {
		compatible = "oplus,virtual_cp";
		oplus,ic_type = <OPLUS_CHG_IC_VIRTUAL_CP>;
		oplus,ic_index = <0>;
		oplus,cp_ic = <&oplus_sc6607_cp &oplus_sc8547_slave_cp>;
		oplus,input_curr_max_ma = <3000 3000>;
		oplus,cp_ic_connect = <OPLUS_CHG_IC_CONNECT_PARALLEL>;
		oplus,main_cp = <0>;
		oplus,reg_proc_node;
	/*
		oplus,cp_strategy = <CP_STRAT_OPEN_BY_CURR>;
		oplus,cp_strategy_data {
			oplus,cp_open_curr_thr_ma = <0 1900>;
			oplus,cp_close_curr_thr_ma = <0 1600>;
		};
	*/
	};
};

&i2c3 {
	status = "okay";
	mediatek,request-cpu-qos;
	clock-frequency = <400000>;//400K
        oplus_sc6607_buck:sc6607-buck@61 {
		status = "okay";
		compatible = "oplus,sc6607-buck";
		reg = <0x61>;

		oplus,irq_gpio = <&pio 6 0x00>;
		pinctrl-names = "charging_inter_active","charging_inter_sleep";

		pinctrl-0 = <&splitchg_inter_active>;
		pinctrl-1 = <&splitchg_inter_sleep>;
		sc,vsys-limit = <3400>;
		sc,vbat = <4450>;
		sc,charge-curr = <2000>;
		sc,iindpm-disable = <0>;
		sc,input-curr-limit = <500>;
		sc,ico-enable = <0>;
		sc,precharge-volt = <0>;      /* 0:2700mv , 1:3000mv */
		sc,precharge-curr = <500>;
		sc,term-en = <0>;
		sc,term-curr = <100>;     /* ma */
		sc,rechg-dis = <1>;
		sc,boost-voltage = <5000>;
		sc,boost-max-current = <1500>;
		sc,conv-ocp-dis = <0>;
		sc,tsbat-jeita-dis = <1>;
		sc,vpmid-ovp-otg-dis = <0>;
		sc,vbat-ovp-buck-dis = <0>;
		sc,ibat-ocp = <1>;    /* 0:12A , 1:16A */
		sc,charge-detect-enable;
		sc,batfet_rst_en = <1>;
		sc,disable-qc;
		sc,cc_pull_up_idrive = <0x09>;
		sc,cc_pull_down_idrive = <0x43>;
		sc,continuous_time = <0x4E>;
		sc,bmc_width = <0x86 0x3d 0x3b 0x10>;
		oplus,disable_tcpc_irq;
		charger_name = "primary_chg";
		//oplus,not_support_usb_btb;
		oplus,usb_aicl_enhance;
		oplus,use_vooc_phy;
		oplus,ic_index = <0>;
		oplus,ic_type = <OPLUS_CHG_IC_BUCK>;
		oplus,sc6607_ntc_surport_1000k = <
			(-40) 4251000 (-39) 3962000 (-38) 3695000 (-37) 3447000 (-36) 3218000 (-35) 3005000
			(-34) 2807000 (-33) 2624000 (-32) 2454000 (-31) 2296000 (-30) 2149000 (-29) 2012000
			(-28) 1885000 (-27) 1767000 (-26) 1656000 (-25) 1554000 (-24) 1458000 (-23) 1369000
			(-22) 1286000 (-21) 1208000 (-20) 1135000 (-19) 1068000 (-18) 1004000 (-17) 945000
			(-16) 889600 (-15) 837800 (-14) 789300 (-13) 743900 (-12) 701300 (-11) 661500
			(-10) 624100 (-9) 589000 (-8) 556200 (-7) 525300 (-6) 496300 (-5) 469100
			(-4) 443500 (-3) 419500 (-2) 396900 (-1) 375600 0 355600 1 336800
			2 319100 3 302400 4 286700 5 271800 6 257800 7 244700
			8 232200 9 220500 10 209400 11 198900 12 189000 13 179700
			14 170900 15 162500 16 154600 17 147200 18 140100 19 133400
			20 127000 21 121000 22 115400 23 110000 24 104800 25 100000
			26 95400 27 91040 28 86900 29 82970 30 79230 31 75690
			32 72320 33 69120 34 66070 35 63180 36 60420 37 57810
			38 55310 39 52940 40 50680 41 48530 42 46490 43 44530
			44 42670 45 40900 46 39210 47 37600 48 36060 49 34600
			50 33190 51 31860 52 30580 53 29360 54 28200 55 27090
			56 26030 57 25010 58 24040 59 23110 60 22220 61 21370
			62 20560 63 19780 64 19040 65 18320 66 17640 67 16990
			68 16360 69 15760 70 15180 71 14630 72 14100 73 13600
			74 13110 75 12640 76 12190 77 11760 78 11350 79 10960
			80 10580 81 10210 82 9859 83 9522 84 9198 85 8887
			86 8587 87 8299 88 8022 89 7756 90 7500 91 7254
			92 7016 93 6788 94 6568 95 6357 96 6153 97 5957
			98 5768 99 5586 100 5410 101 5241 102 5078 103 4921
			104 4769 105 4623 106 4482 107 4346 108 4215 109 4088
			110 3966 111 3848 112 3734 113 3624 114 3518 115 3415
			116 3316 117 3220 118 3128 119 3038 120 2952 121 2868
			122 2787 123 2709 124 2634 125 2561 125 2561 125 2561
			125 2561 125 2561 125 2561 125 2561 125 2561 125 2561
			125 2561 125 2561 125 2561 125 2561 125 2561 125 2561>;
	};
	oplus_sc6607_phy:oplus-sc6607-phy {
		compatible = "oplus,sc6607-voocphy";
		reg = <0x60>;//virtual address for v2
		oplus,ic_index = <0>;
		oplus,ic_type = <OPLUS_CHG_IC_VPHY>;
		oplus,vooc-version = <VOOC_VERSION_5_0>;
		oplus,vac_support;
		oplus_spec,voocphy_dual_cp_support;
		oplus_spec,slave_cp_enable_thr = <1400>;		//2000-100mA
		oplus_spec,slave_cp_disable_thr_high = <1100>;	//1500+100mA
		oplus_spec,copycat_vooc_support;
		oplus_spec,copycat_vooc_accuracy_value = <105>;
		oplus,copycat-vooc-count = <4>;
		ovp_reg = <0x36>; /* 4850mv */
		ocp_reg = <0xf>;    /* 4.75A*/
		oplus_spec,voocphy_current_default = <73>;/*7300mA*/
		oplus_spec,svooc_cool_down_current_limit = <146 20 20 24 30 34 40 44 50 54 60 64 70 74>;
		oplus_spec,vooc_cool_down_current_limit = <73 20 20 24 30 34 40 44 50 54 60 64 70 74>;
		oplus_spec,ap_control_allow;
		oplus,abnormal_adapter_current = <CP_CURR_LIMIT_7BIT_15_0A CP_CURR_LIMIT_7BIT_15_0A
						CP_CURR_LIMIT_7BIT_12_6A CP_CURR_LIMIT_7BIT_12_6A
						CP_CURR_LIMIT_7BIT_10_0A CP_CURR_LIMIT_7BIT_10_0A
						CP_CURR_LIMIT_7BIT_8_0A CP_CURR_LIMIT_7BIT_8_0A
						CP_CURR_LIMIT_7BIT_6_0A CP_CURR_LIMIT_7BIT_6_0A
						CP_CURR_LIMIT_7BIT_4_0A CP_CURR_LIMIT_7BIT_4_0A>;
		oplus,abnormal_over_80w_adapter_current = <CP_CURR_LIMIT_7BIT_15_0A CP_CURR_LIMIT_7BIT_15_0A
						CP_CURR_LIMIT_7BIT_14_0A CP_CURR_LIMIT_7BIT_14_0A
						CP_CURR_LIMIT_7BIT_12_0A CP_CURR_LIMIT_7BIT_12_0A
						CP_CURR_LIMIT_7BIT_10_0A CP_CURR_LIMIT_7BIT_10_0A
						CP_CURR_LIMIT_7BIT_8_0A CP_CURR_LIMIT_7BIT_8_0A
						CP_CURR_LIMIT_7BIT_6_0A CP_CURR_LIMIT_7BIT_6_0A
						CP_CURR_LIMIT_7BIT_4_0A CP_CURR_LIMIT_7BIT_4_0A>;

		oplus_spec,vooc_little_cold_full_voltage = <4570>;
		oplus_spec,vooc_cool_full_voltage = <4570>;
		oplus_spec,vooc_warm_full_voltage = <4130>;
		oplus_spec,vooc_1time_full_voltage = <4580>;
		oplus_spec,vooc_ntime_full_voltage = <4570>;

		oplus_spec,vooc_multistep_initial_batt_temp = <1000>;
		oplus_spec,fastchg_timeout_time_init = <175620>;
		oplus_spec,vooc_little_cool_temp = <160>;
		oplus_spec,vooc_little_cool_high_temp = <210>;
		oplus_spec,vooc_cool_temp = <120>;
		oplus_spec,vooc_little_cold_temp = <50>;
		oplus_spec,vooc_normal_low_temp = <350>;
		oplus_spec,vooc_strategy_normal_current = <100>;
		oplus_spec,vooc_normal_to_little_cool_current = <100>;
		oplus_spec,vooc_over_high_temp = <510>;
		oplus_spec,vooc_low_temp = <0>;
		oplus_spec,vooc_high_temp = <500>;
		oplus_spec,vooc_low_soc = <0>;
		oplus_spec,vooc_high_soc = <90>;
		oplus_spec,vooc_normal_high_temp = <440>;
		oplus_spec,vooc_warm_allow_vol = <4000>;
		oplus_spec,vooc_warm_allow_soc = <50>;
		oplus_spec,impedance_calculation_newmethod;
		//oplus_spec,svooc_circuit_r_l = <0x18>;
		//oplus_spec,svooc_circuit_r_h = <0x2>;/* 65 mR */

		oplus_spec,voocphy_ibat_over_current = <16000>;
		oplus_spec,voocphy_cp_max_ibus = <4750>;
		oplus_spec,voocphy_svooc_cp_max_ibus = <4750>;
		oplus_spec,voocphy_vooc_cp_max_ibus = <3500>;
		oplus_spec,batt_pwd_curr_thd1 = <4300>;
		oplus_spec,batt_pwd_vol_thd1 = <4514>;

		oplus_spec,vooc_strategy1_batt_high_temp0 = <385>;
		oplus_spec,vooc_strategy1_batt_high_temp1 = <395>;
		oplus_spec,vooc_strategy1_batt_high_temp2 = <420>;
		oplus_spec,vooc_strategy1_batt_low_temp2 = <410>;
		oplus_spec,vooc_strategy1_batt_low_temp1 = <385>;
		oplus_spec,vooc_strategy1_batt_low_temp0 = <375>;
		oplus_spec,vooc_strategy1_high_current0 = <80>;
		oplus_spec,vooc_strategy1_high_current1 = <61>;
		oplus_spec,vooc_strategy1_high_current2 = <40>;
		oplus_spec,vooc_strategy1_low_current2 = <40>;
		oplus_spec,vooc_strategy1_low_current1 = <61>;
		oplus_spec,vooc_strategy1_low_current0 = <80>;

		oplus_spec,voocphy_freq_mincore = <2000000>;
		oplus_spec,voocphy_freq_midcore = <2000000>;
		oplus_spec,voocphy_freq_maxcore = <2200000>;
		oplus_spec,voocphy_current_change_timeout = <100>;

		svooc_batt_sys_curve = <0 1 0 1 0 0 0	// 4000mA
					1 1 1 1 0 0 0	// 4604mV
					0 0 1 1 0 1 0	// 2600mA
					1 1 1 1 0 0 0	// 4604mV
					0 0 0 1 0 1 1	// 1100mA
					1 1 1 1 0 0 0>;	// 4604mV

		vooc_batt_sys_curve =  <0 1 0 1 0 0 0	// 4000mA
					1 1 1 1 0 0 0	// 4604mV
					0 0 1 1 0 1 0	// 2600mA
					1 1 1 1 0 0 0	// 4604mV
					0 0 0 1 0 1 1	// 1100mA
					1 1 1 1 0 0 0>;	// 4604mV

		svooc_lcf_strategy {
			oplus,temp_type = <OPLUS_STRATEGY_USE_SHELL_TEMP>;
			oplus,temp_range = <0 50 120 160 210 380 440>;

			strategy_temp_range_curves {
				strategy_temp_range_t0 =	<980 4570 0
								 930 4560 0
								 880 4550 0
								 830 4540 0
								 780 4530 1>;
				strategy_temp_range_t1 =	<1090 4570 0
								 1040 4565 0
								 990 4550 0
								 890 4540 0
								 790 4530 1>;
				strategy_temp_range_t2 =	<1390 4570 0
								 1340 4565 0
								 1240 4550 0
								 1140 4540 0
								 990 4530 1>;
				strategy_temp_range_t3 =	<1390 4570 0
								 1340 4565 0
								 1240 4550 0
								 1140 4540 0
								 990 4530 1>;
				strategy_temp_range_t4 =	<2250 4558 0
								 2100 4550 0
								 1900 4541 0
								 1700 4532 0
								 1500 4510 1>;
				strategy_temp_range_t5 =	<2850 4558 0
								 2650 4550 0
								 2100 4532 0
								 1550 4510 0
								 1000 4490 1>;
			};
		};

		svooc_charge_strategy {
			strategy_soc_0_to_50 {
				strategy_temp_little_cold =	<4150 22 0 0 0
								 4150 20 0 0 0
								 4560 15 0 0 0
								 4570 10 1 0 0>;
				strategy_temp_cool =		<4150 39 0 0 0
								 4150 35 0 0 0
								 4150 30 0 0 0
								 4510 29 0 0 0
								 4510 25 0 0 0
								 4510 20 0 0 0
								 4560 15 0 0 0
								 4570 10 1 0 0>;
				strategy_temp_little_cool = 	<4150 59 0 0 0
								 4150 55 0 0 0
								 4150 50 0 0 0
								 4510 42 0 0 0
								 4510 40 0 0 0
								 4510 35 0 0 0
								 4560 32 0 0 0
								 4560 30 0 0 0
								 4560 25 0 0 0
								 4560 20 0 0 0
								 4560 15 0 0 0
								 4570 10 1 0 0>;
				strategy_temp_little_cool_high = <4150 59 0 0 0
								 4150 55 0 0 0
								 4150 50 0 0 0
								 4510 42 0 0 0
								 4510 40 0 0 0
								 4510 35 0 0 0
								 4560 32 0 0 0
								 4560 30 0 0 0
								 4560 25 0 0 0
								 4560 20 0 0 0
								 4560 15 0 0 0
								 4570 10 1 0 0>;
				strategy_temp_normal_low =	<4250 73 0 60 0
								 4280 65 0 160 0
								 4280 50 0 360 0
								 4510 45 0 0 0
								 4510 40 0 0 0
								 4560 36 0 0 0
								 4560 35 0 0 0
								 4560 30 0 0 0
								 4560 25 0 0 0
								 4560 20 0 0 0
								 4560 15 0 0 0
								 4565 12 0 0 0
								 4550 10 1 0 0>;
				strategy_temp_normal_high =	<4250 73 0 60 0
								 4280 65 0 160 0
								 4280 50 0 360 0
								 4510 45 0 0 0
								 4510 40 0 0 0
								 4560 36 0 0 0
								 4560 35 0 0 0
								 4560 30 0 0 0
								 4560 25 0 0 0
								 4560 20 0 0 0
								 4565 15 0 0 0
								 4550 12 0 0 0
								 4550 10 1 0 0>;
				strategy_temp_warm =		<4120 18 0 0 0
								 4120 15 0 0 0
								 4130 10 1 0 0>;
			};

			strategy_soc_0_to_50_mid { /* 21 ~ 35 */
				strategy_temp_little_cold =	<4150 22 0 0 0
								 4150 20 0 0 0
								 4560 15 0 0 0
								 4570 10 1 0 0>;
				strategy_temp_cool =		<4150 39 0 0 0
								 4150 35 0 0 0
								 4150 30 0 0 0
								 4510 29 0 0 0
								 4510 25 0 0 0
								 4510 20 0 0 0
								 4560 15 0 0 0
								 4570 10 1 0 0>;
				strategy_temp_little_cool = 	<4150 59 0 0 0
								 4150 55 0 0 0
								 4150 50 0 0 0
								 4510 42 0 0 0
								 4510 40 0 0 0
								 4510 35 0 0 0
								 4560 32 0 0 0
								 4560 30 0 0 0
								 4560 25 0 0 0
								 4560 20 0 0 0
								 4560 15 0 0 0
								 4570 10 1 0 0>;
				strategy_temp_little_cool_high = <4150 59 0 0 0
								 4150 55 0 0 0
								 4150 50 0 0 0
								 4510 42 0 0 0
								 4510 40 0 0 0
								 4510 35 0 0 0
								 4560 32 0 0 0
								 4560 30 0 0 0
								 4560 25 0 0 0
								 4560 20 0 0 0
								 4560 15 0 0 0
								 4570 10 1 0 0>;
				strategy_temp_normal_low =	<4250 73 0 60 0
								 4280 65 0 160 0
								 4280 50 0 360 0
								 4510 45 0 0 0
								 4510 40 0 0 0
								 4560 36 0 0 0
								 4560 35 0 0 0
								 4560 30 0 0 0
								 4560 25 0 0 0
								 4560 20 0 0 0
								 4560 15 0 0 0
								 4565 12 0 0 0
								 4550 10 1 0 0>;
				strategy_temp_normal_high =	<4250 73 0 60 0
								 4280 65 0 160 0
								 4280 50 0 360 0
								 4510 45 0 0 0
								 4510 40 0 0 0
								 4560 36 0 0 0
								 4560 35 0 0 0
								 4560 30 0 0 0
								 4560 25 0 0 0
								 4560 20 0 0 0
								 4565 15 0 0 0
								 4550 12 0 0 0
								 4550 10 1 0 0>;
				strategy_temp_warm =		<4120 18 0 0 0
								 4120 15 0 0 0
								 4130 10 1 0 0>;
			};

			strategy_soc_0_to_50_high { /* 36 ~ 55 */
				strategy_temp_little_cold =	<4150 20 0 0 0
								 4560 15 0 0 0
								 4570 10 1 0 0>;
				strategy_temp_cool =		<4510 25 0 0 0
								 4510 20 0 0 0
								 4560 15 0 0 0
								 4570 10 1 0 0>;
				strategy_temp_little_cool = 	<4510 40 0 0 0
								 4510 35 0 0 0
								 4560 32 0 0 0
								 4560 30 0 0 0
								 4560 25 0 0 0
								 4560 20 0 0 0
								 4560 15 0 0 0
								 4570 10 1 0 0>;
				strategy_temp_little_cool_high = <4510 40 0 0 0
								 4510 35 0 0 0
								 4560 32 0 0 0
								 4560 30 0 0 0
								 4560 25 0 0 0
								 4560 20 0 0 0
								 4560 15 0 0 0
								 4570 10 1 0 0>;
				strategy_temp_normal_low =	<4250 73 0 60 0
								 4280 65 0 160 0
								 4280 50 0 360 0
								 4510 45 0 0 0
								 4510 40 0 0 0
								 4560 36 0 0 0
								 4560 35 0 0 0
								 4560 30 0 0 0
								 4560 25 0 0 0
								 4560 20 0 0 0
								 4560 15 0 0 0
								 4565 12 0 0 0
								 4550 10 1 0 0>;
				strategy_temp_normal_high =	<4250 73 0 60 0
								 4280 65 0 160 0
								 4280 50 0 360 0
								 4510 45 0 0 0
								 4510 40 0 0 0
								 4560 36 0 0 0
								 4560 35 0 0 0
								 4560 30 0 0 0
								 4560 25 0 0 0
								 4560 20 0 0 0
								 4565 15 0 0 0
								 4550 12 0 0 0
								 4550 10 1 0 0>;
				strategy_temp_warm =		<4120 18 0 0 0
								 4120 15 0 0 0
								 4130 10 1 0 0>;
			};

			strategy_soc_50_to_75 {
				strategy_temp_little_cold =	<4560 15 0 0 0
								 4570 10 1 0 0>;
				strategy_temp_cool =		<4560 15 0 0 0
								 4570 10 1 0 0>;
				strategy_temp_little_cool = 	<4560 20 0 0 0
								 4560 15 0 0 0
								 4570 10 1 0 0>;
				strategy_temp_little_cool_high = <4560 20 0 0 0
								 4560 15 0 0 0
								 4570 10 1 0 0>;
				strategy_temp_normal_low =	<4560 25 0 0 0
								 4560 20 0 0 0
								 4560 15 0 0 0
								 4565 12 0 0 0
								 4550 10 1 0 0>;
				strategy_temp_normal_high =	<4560 30 0 0 0
								 4560 25 0 0 0
								 4560 20 0 0 0
								 4565 15 0 0 0
								 4550 12 0 0 0
								 4550 10 1 0 0>;
				strategy_temp_warm =		<4130 10 1 0 0>;//no fastcharge
			};

			strategy_soc_75_to_85 {
				strategy_temp_little_cold = 	<4570 10 1 0 0>;
				strategy_temp_cool =		<4570 10 1 0 0>;
				strategy_temp_little_cool =	<4560 15 0 0 0
								 4570 10 1 0 0>;
				strategy_temp_little_cool_high = <4560 15 0 0 0
								 4570 10 1 0 0>;
				strategy_temp_normal_low =	<4560 15 0 0 0
								 4565 12 1 0 0>;
				strategy_temp_normal_high =	<4560 20 0 0 0
								 4565 15 1 0 0>;
				strategy_temp_warm =		<4130 10 1 0 0>;//no fastcharge
			};

			strategy_soc_85_to_90 {
				strategy_temp_little_cold = 	<4570 10 1 0 0>;
				strategy_temp_cool =		<4570 10 1 0 0>;
				strategy_temp_little_cool =	<4570 10 1 0 0>;
				strategy_temp_little_cool_high =<4570 10 1 0 0>;
				strategy_temp_normal_low =	<4565 12 1 0 0>;
				strategy_temp_normal_high =	<4565 15 1 0 0>;
				strategy_temp_warm =		<4130 10 1 0 0>;//no fastcharge
			};
		};

		vooc_charge_strategy {
			strategy_soc_0_to_50 {
				strategy_temp_little_cold =	<4150 44 0 0 0
								 4150 40 0 0 0
								 4560 30 0 0 0
								 4570 20 1 0 0>;
				strategy_temp_cool =		<4150 60 0 0 0
								 4510 58 0 0 0
								 4510 50 0 0 0
								 4510 40 0 0 0
								 4560 30 0 0 0
								 4570 20 1 0 0>;
				strategy_temp_little_cool =	<4560 60 0 0 0
								 4560 50 0 0 0
								 4560 40 0 0 0
								 4560 30 0 0 0
								 4570 20 1 0 0>;
				strategy_temp_little_cool_high =<4560 60 0 0 0
								 4560 50 0 0 0
								 4560 40 0 0 0
								 4560 30 0 0 0
								 4570 20 1 0 0>;
				strategy_temp_normal_low =	<4560 60 0 0 0
								 4560 50 0 0 0
								 4560 40 0 0 0
								 4560 30 0 0 0
								 4565 24 0 0 0
								 4550 20 1 0 0>;
				strategy_temp_normal_high =	<4560 60 0 0 0
								 4560 50 0 0 0
								 4560 40 0 0 0
								 4565 30 0 0 0
								 4550 24 0 0 0
								 4550 20 1 0 0>;
				strategy_temp_warm =		<4120 36 0 0 0
								 4120 30 0 0 0
								 4130 20 1 0 0>;
			};
			strategy_soc_0_to_50_mid {
				strategy_temp_little_cold =	<4150 44 0 0 0
								 4150 40 0 0 0
								 4560 30 0 0 0
								 4570 20 1 0 0>;
				strategy_temp_cool =		<4150 60 0 0 0
								 4510 58 0 0 0
								 4510 50 0 0 0
								 4510 40 0 0 0
								 4560 30 0 0 0
								 4570 20 1 0 0>;
				strategy_temp_little_cool =	<4560 60 0 0 0
								 4560 50 0 0 0
								 4560 40 0 0 0
								 4560 30 0 0 0
								 4570 20 1 0 0>;
				strategy_temp_little_cool_high =<4560 60 0 0 0
								 4560 50 0 0 0
								 4560 40 0 0 0
								 4560 30 0 0 0
								 4570 20 1 0 0>;
				strategy_temp_normal_low =	<4560 60 0 0 0
								 4560 50 0 0 0
								 4560 40 0 0 0
								 4560 30 0 0 0
								 4565 24 0 0 0
								 4550 20 1 0 0>;
				strategy_temp_normal_high =	<4560 60 0 0 0
								 4560 50 0 0 0
								 4560 40 0 0 0
								 4565 30 0 0 0
								 4550 24 0 0 0
								 4550 20 1 0 0>;
				strategy_temp_warm =		<4120 36 0 0 0
								 4120 30 0 0 0
								 4130 20 1 0 0>;
			};
			strategy_soc_0_to_50_high {
				strategy_temp_little_cold =	<4150 40 0 0 0
								 4560 30 0 0 0
								 4570 20 1 0 0>;
				strategy_temp_cool =		<4510 50 0 0 0
								 4510 40 0 0 0
								 4560 30 0 0 0
								 4570 20 1 0 0>;
				strategy_temp_little_cool =	<4560 60 0 0 0
								 4560 50 0 0 0
								 4560 40 0 0 0
								 4560 30 0 0 0
								 4570 20 1 0 0>;
				strategy_temp_little_cool_high =<4560 60 0 0 0
								 4560 50 0 0 0
								 4560 40 0 0 0
								 4560 30 0 0 0
								 4570 20 1 0 0>;
				strategy_temp_normal_low =	<4560 60 0 0 0
								 4560 50 0 0 0
								 4560 40 0 0 0
								 4560 30 0 0 0
								 4565 24 0 0 0
								 4550 20 1 0 0>;
				strategy_temp_normal_high =	<4560 60 0 0 0
								 4560 50 0 0 0
								 4560 40 0 0 0
								 4565 30 0 0 0
								 4550 24 0 0 0
								 4550 20 1 0 0>;
				strategy_temp_warm =		<4120 36 0 0 0
								 4120 30 0 0 0
								 4130 20 1 0 0>;
			};

			strategy_soc_50_to_75 {
				strategy_temp_little_cold =	<4560 30 0 0 0
								 4570 20 1 0 0>;
				strategy_temp_cool =		<4560 30 0 0 0
								 4570 20 1 0 0>;
				strategy_temp_little_cool =	<4560 40 0 0 0
								 4560 30 0 0 0
								 4570 20 1 0 0>;
				strategy_temp_little_cool_high =<4560 40 0 0 0
								 4560 30 0 0 0
								 4570 20 1 0 0>;
				strategy_temp_normal_low =	<4560 50 0 0 0
								 4560 40 0 0 0
								 4560 30 0 0 0
								 4565 24 0 0 0
								 4550 20 1 0 0>;
				strategy_temp_normal_high =	<4560 50 0 0 0
								 4560 40 0 0 0
								 4565 30 0 0 0
								 4550 24 0 0 0
								 4550 20 1 0 0>;
				strategy_temp_warm =		<4130 20 1 0 0>;
			};

			strategy_soc_75_to_85 {
				strategy_temp_little_cold =	<4570 20 1 0 0>;
				strategy_temp_cool =		<4570 20 1 0 0>;
				strategy_temp_little_cool =	<4560 30 0 0 0
								 4570 20 1 0 0>;
				strategy_temp_little_cool_high =<4560 30 0 0 0
								 4570 20 1 0 0>;
				strategy_temp_normal_low =	<4560 30 0 0 0
								 4565 24 0 0 0
								 4550 20 1 0 0>;
				strategy_temp_normal_high =	<4560 40 0 0 0
								 4565 30 0 0 0
								 4550 24 0 0 0
								 4550 20 1 0 0>;
				strategy_temp_warm =		<4130 20 1 0 0>;
			};

			strategy_soc_85_to_90 {
				strategy_temp_little_cold =	<4570 20 1 0 0>;
				strategy_temp_cool =		<4570 20 1 0 0>;
				strategy_temp_little_cool =	<4570 20 1 0 0>;
				strategy_temp_little_cool_high =<4570 20 1 0 0>;
				strategy_temp_normal_low =	<4565 24 0 0 0
								 4550 20 1 0 0>;
				strategy_temp_normal_high =	<4565 30 0 0 0
								 4550 24 0 0 0
								 4550 20 1 0 0>;
				strategy_temp_warm = 		<4130 20 1 0 0>;
			};
		};
		oplus_sc6607_cp:oplus-sc6607-cp {
			oplus,ic_type = <OPLUS_CHG_IC_CP>;
			oplus,ic_index = <0>;
			oplus,ic_func_group = <&sc6607_cp_groups>;
		};
		oplus_virtual_dpdm_switch: oplus,virtual_dpdm_switch {
			oplus,ic_type = <OPLUS_CHG_IC_MISC>;
			oplus,ic_index = <0>;
		};
	};
};

&i2c6 {
	status = "okay";
	clock-frequency = <400000>;
	oplus_sc8547_slave: sc8547-charger-slave@6F{
		status = "okay";
		compatible = "slave_vphy_sc8547";
		reg = <0x6F>;

		ocp_reg = <0xd>;
		ovp_reg = <0x36>;/* vbat ovp 4.85v */
		oplus_sc8547_slave_cp: oplus,sc8547_slave_cp {
			oplus,ic_type = <OPLUS_CHG_IC_CP>;
			oplus,ic_index = <1>;
			oplus,ic_func_group = <&sc8547_cp_groups>;
		};
	};
};

#include "mediatek/oplus_charge_BaikalL5_PD.dtsi"
#include "mediatek/oplus_charge_BaikalL5_pps_33w.dtsi"
